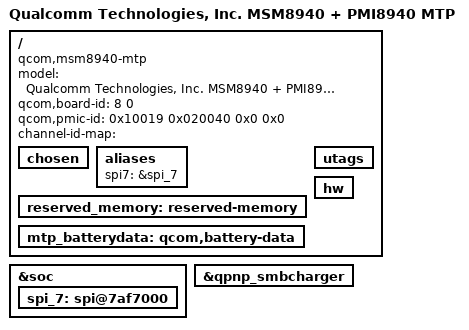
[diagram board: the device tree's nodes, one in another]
/* Copyright (c) 2018, The Linux Foundation. All rights reserved.
 *
 * This program is free software; you can redistribute it and/or modify
 * it under the terms of the GNU General Public License version 2 and
 * only version 2 as published by the Free Software Foundation.
 *
 * This program is distributed in the hope that it will be useful,
 * but WITHOUT ANY WARRANTY; without even the implied warranty of
 * MERCHANTABILITY or FITNESS FOR A PARTICULAR PURPOSE.  See the
 * GNU General Public License for more details.
 */

#include "msm8940.dtsi"
#include "msm8940-pmi8940.dtsi"

&soc {
	spi_7: spi@7af7000 { };
};

/ {
/*
 * Some nodes need labels assigned to appear in __symbols__
 */
	model = "Qualcomm Technologies, Inc. MSM8940 + PMI8940 MTP";
	compatible = "qcom,msm8940-mtp", "qcom,msm8940", "qcom,mtp";
	qcom,board-id = <8 0>;
	qcom,pmic-id = <0x10019 0x020040 0x0 0x0>;
	channel-id-map = "";

	chosen: chosen { };
	aliases: aliases {
		spi7 = &spi_7;
	};
	reserved_memory: reserved-memory { };
	mtp_batterydata: qcom,battery-data {};
	utags: utags { };
	hw: hw { };
};

&soc {
	/delete-node/ hbtp;
};

&qpnp_smbcharger {
	/delete-property/ qcom,sw-jeita-enable;
	/delete-property/ qcom,step-charging-enable;
	/delete-property/ qcom,hw-die-temp-mitigation;
	/delete-property/ qcom,hw-connector-mitigation;
};
